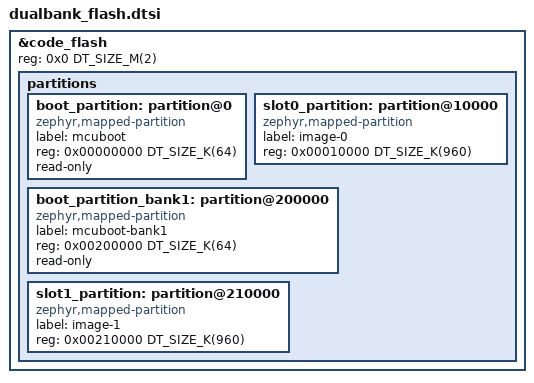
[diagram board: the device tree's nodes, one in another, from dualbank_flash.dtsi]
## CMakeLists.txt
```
cmake_minimum_required(VERSION 3.20.0)
find_package(Zephyr REQUIRED HINTS $ENV{ZEPHYR_BASE})
project(ra6m5_dualbank_xip)

target_sources(app PRIVATE
    src/main.c
    src/comms.c
    src/menu.c
    src/xmodem.c
    src/downloader_thread_entry.c
    src/blinky_thread_entry.c
    src/interrupt_maker.c)

if(CONFIG_BOOTLOADER_MCUBOOT)
  set(signed_hex ${ZEPHYR_BINARY_DIR}/zephyr.signed.hex)
  set(signed_bin ${ZEPHYR_BINARY_DIR}/zephyr.signed.bin)

  add_custom_target(bank_images ALL
    COMMAND ${CMAKE_COMMAND} -E copy ${signed_hex} ${ZEPHYR_BINARY_DIR}/app_bank0.hex
    COMMAND ${CMAKE_OBJCOPY} -I ihex -O ihex --change-addresses 0x200000
            ${signed_hex} ${ZEPHYR_BINARY_DIR}/app_bank1_rfp.hex
    COMMAND ${CMAKE_OBJCOPY} -I ihex -O ihex --change-addresses 0x100000
            ${signed_hex} ${ZEPHYR_BINARY_DIR}/app_bank1_jlink.hex
    COMMAND ${CMAKE_COMMAND} -E copy ${signed_bin} ${ZEPHYR_BINARY_DIR}/app_xmodem.bin
  )
  add_dependencies(bank_images ${logical_target_for_zephyr_elf})
endif()
```

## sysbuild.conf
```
SB_CONFIG_BOOTLOADER_MCUBOOT=y # Includes mcuboot

SB_CONFIG_MCUBOOT_MODE_DIRECT_XIP=y # Sets mcuboot to use direct xip

SB_CONFIG_MCUBOOT_DIRECT_XIP_GENERATE_VARIANT=n # stops sysbuild from making a slot 1 variant, wrong address

SB_CONFIG_BOOT_SIGNATURE_TYPE_ECDSA_P256=y # optional, more compact encryption
```

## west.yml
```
manifest:
  remotes:
    - name: P-Harwood
      url-base: https://github.com/P-Harwood

  projects:
    - name: zephyr
      remote: P-Harwood
      repo-path: zephyr_Exp
      revision: dualbank-v2.2.3
      clone-depth: 1
      import:
        name-allowlist:
          - cmsis_6
          - hal_renesas

    - name: mcuboot
      remote: P-Harwood
      repo-path: mcuboot
      revision: ra6m5-erase-size-v2
      path: bootloader/mcuboot

  self:
    path: applications/db_xip
```

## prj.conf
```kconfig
CONFIG_MCUBOOT_GENERATE_CONFIRMED_IMAGE=y # Make the confirmed file for initial flashing

CONFIG_FLASH=y # include the flash drivers
CONFIG_FLASH_MAP=y # include the named partitions so runtime code can access them
CONFIG_STREAM_FLASH=y # buffered flash writes, used by the image manager
CONFIG_IMG_MANAGER=y # Zephyrs tool for writing firmware into a slot

CONFIG_FLASH_RENESAS_RA_HP_BANK_SWAP=y # Includes flash_ex_op and bank swap
CONFIG_FLASH_EX_OP_ENABLED=y # enabled version of flash_ex_op

CONFIG_GPIO=y # gpio pins support
CONFIG_REBOOT=y # allows software rebooting

CONFIG_SERIAL=y
CONFIG_UART_INTERRUPT_DRIVEN=y # comms.c receives on the UART interrupt
CONFIG_CONSOLE=y # printk goes to the same UART, output only
CONFIG_PRINTK=y

# main thread stack size
CONFIG_MAIN_STACK_SIZE=2048
CONFIG_HW_STACK_PROTECTION=y
CONFIG_IMG_ERASE_PROGRESSIVELY=y


CONFIG_COUNTER=y
CONFIG_FLASH_RENESAS_RA_HP_IRQ_ENABLED=y
```

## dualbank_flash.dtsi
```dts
&code_flash {
	reg = <0x0 DT_SIZE_M(2)>;
	ranges = <0x0 0x0 DT_SIZE_M(3)>;

	partitions {
		#address-cells = <1>;
		#size-cells = <1>;
		ranges;

		boot_partition: partition@0 {
			compatible = "zephyr,mapped-partition";
			label = "mcuboot";
			reg = <0x00000000 DT_SIZE_K(64)>;
			read-only;
		};

		slot0_partition: partition@10000 {
			compatible = "zephyr,mapped-partition";
			label = "image-0";
			reg = <0x00010000 DT_SIZE_K(960)>;
		};
		boot_partition_bank1: partition@200000 {
			compatible = "zephyr,mapped-partition";
			label = "mcuboot-bank1";
			reg = <0x00200000 DT_SIZE_K(64)>;
			read-only;
		};

		slot1_partition: partition@210000 {
			compatible = "zephyr,mapped-partition";
			label = "image-1";
			reg = <0x00210000 DT_SIZE_K(960)>;
		};
	};
};
```

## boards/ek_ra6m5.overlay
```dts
#include "../dualbank_flash.dtsi"

/ {
	chosen {
		zephyr,code-partition = &slot0_partition;
	};
};
&agt0 {
	interrupts = <86 1>, <87 1>;
	renesas,count-source = "AGT_CLOCK_PCLKB";
	interrupt-names = "agti", "agtcmai";
	status = "okay";

	counter0: counter {
		status = "okay";
	};
};
```

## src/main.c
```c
#include <zephyr/kernel.h>
#include <zephyr/dfu/mcuboot.h>
#include "header.h"
#include <zephyr/drivers/gpio.h>

int main(void)
{
	dual_bank_info();
	return 0;
}
```

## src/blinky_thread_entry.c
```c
#include <zephyr/kernel.h>
#include <zephyr/drivers/gpio.h>
static const struct gpio_dt_spec led = GPIO_DT_SPEC_GET(DT_ALIAS(led0), gpios);


void blinky_thread_entry(void *p1, void *p2, void *p3)
{
    ARG_UNUSED(p1);
    ARG_UNUSED(p2);
    ARG_UNUSED(p3);
    if (!gpio_is_ready_dt(&led)) {
        return;
    }
    gpio_pin_configure_dt(&led, GPIO_OUTPUT_ACTIVE);
    while (1) {
        gpio_pin_toggle_dt(&led);
        k_msleep(2000);
    }
}
K_THREAD_DEFINE(blinky_tid, 1024, blinky_thread_entry,
                NULL, NULL, NULL, 7, 0, 0);
```

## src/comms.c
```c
#include "comms.h"


#include <zephyr/kernel.h>
#include <zephyr/device.h>
#include <zephyr/drivers/uart.h>


#if defined(COMMS_USB)
#include <zephyr/usb/usb_device.h>
#define COMMS_DEV_NODE  DT_NODELABEL(cdc_acm_uart0)
#else
#define COMMS_DEV_NODE  DT_CHOSEN(zephyr_console)
#endif


#define RX_QUEUE_BYTES  512


static const struct device *const comms_dev = DEVICE_DT_GET(COMMS_DEV_NODE);


K_MSGQ_DEFINE(rx_q, 1, RX_QUEUE_BYTES, 1);

void comms_flush(void)
{
    k_msgq_purge(&rx_q);
}

static void comms_rx_isr(const struct device *dev, void *user_data)
{
    ARG_UNUSED(user_data);

    uart_irq_update(dev);

    if (uart_irq_rx_ready(dev)) {
        uint8_t byte;

        while (uart_fifo_read(dev, &byte, 1) == 1) {
            (void)k_msgq_put(&rx_q, &byte, K_NO_WAIT);
        }
    }
}




int comms_open(void)
{
    if (!device_is_ready(comms_dev)) {
        return -ENODEV;
    }


#if defined(COMMS_USB)
    int rc = usb_enable(NULL);
    if (rc != 0 && rc != -EALREADY) {
        return rc;
    }
    uint32_t dtr = 0U;
    while (!dtr) {
        uart_line_ctrl_get(comms_dev, UART_LINE_CTRL_DTR, &dtr);
        k_msleep(10);
    }
#endif
    uart_irq_callback_user_data_set(comms_dev, comms_rx_isr, NULL);
    uart_irq_rx_enable(comms_dev);


    return 0;
}


void comms_send(uint8_t *p_src, uint32_t len)
{
    for (uint32_t i = 0U; i < len; i++) {
        uart_poll_out(comms_dev, p_src[i]);
    }
}


int comms_read(uint8_t *p_dest, uint32_t *len, uint32_t timeout_milliseconds)
{
    const bool    forever  = (timeout_milliseconds == NO_TIMEOUT);
    const int64_t deadline = forever ? 0 : (k_uptime_get() + timeout_milliseconds);




    
for (uint32_t i = 0U; i < *len; i++) {
        k_timeout_t wait;


        if (forever) {
            wait = K_FOREVER;
        } else {
            int64_t remaining = deadline - k_uptime_get();
            if (remaining <= 0) {
                *len = i;
                return COMMS_TIMEOUT;
            }
            wait = K_MSEC(remaining);
        }
        if (k_msgq_get(&rx_q, &p_dest[i], wait) != 0) {
            *len = i;
            return COMMS_TIMEOUT;
        }
    }
    return COMMS_OK;
}
```

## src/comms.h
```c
#ifndef COMMS_H_
#define COMMS_H_


#include <stdint.h>
#include <errno.h>


#define COMMS_UART


#define NO_TIMEOUT      0xFFFFFFFFU


#define COMMS_OK        0
#define COMMS_TIMEOUT   (-EAGAIN)


int  comms_open(void);
void comms_send(uint8_t *p_src, uint32_t len);
int  comms_read(uint8_t *p_dest, uint32_t *len, uint32_t timeout_milliseconds);
void comms_flush(void);

#endif
```

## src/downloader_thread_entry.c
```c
#include <zephyr/kernel.h>
#include <zephyr/storage/flash_map.h>
#include <stdio.h>
#include <string.h>
#include <zephyr/dfu/mcuboot.h>

#include "comms.h"
#include "menu.h"
#include "header.h"
#include "interrupt_maker.h"

// MCUBoot magic number to be placed in the header of the image
#define IMAGE_MAGIC 0x96f3b83d  


void downloader_thread_entry(void *p1, void *p2, void *p3)
{
    ARG_UNUSED(p1);
    ARG_UNUSED(p2);
    ARG_UNUSED(p3);


    // Check to see if UART is ready and status is ok
    if (comms_open() != 0) {
        // If the UART is not ready then exit with panic
        k_panic();
    }


    // Infinite loop of running menu during the thread
    while (1) {
        menu();
    }
}


// Define and instantly launch the downloader thread with a piority of 5
K_THREAD_DEFINE(downloader_tid, 4096, downloader_thread_entry,
                   NULL, NULL, NULL, 5, 0, 0);






// Struct which contains image version to be put into the header of the image
struct image_version {
    uint8_t  iv_major;
    uint8_t  iv_minor;
    uint16_t iv_revision;
    uint32_t iv_build_num;
};


// Image header which brings all the information together
struct image_header {
    uint32_t ih_magic;
    uint32_t ih_load_addr;
    uint16_t ih_hdr_size;            
    uint16_t ih_protect_tlv_size;    
    uint32_t ih_img_size;            
    uint32_t ih_flags;              
    struct image_version ih_ver;
    uint32_t _pad1;
};



/** @brief Check if dualbank mode is enabled
 *	@retval boolean is dualbank enabled
*/
static bool dual_bank_mode(void)
{
	bool enabled = (sys_read32(DUALSEL_ADDR) & BANKMD_MASK) == 0U;
	return enabled;
}

/** @brief Check if the banks have been swapped by checking the bank swap register
 *	@retval boolean is dualbank enabled
*/
static bool banks_swapped(void)
{
	bool swapped = (sys_read32(BANKSEL_ADDR) & BANKSWP_MASK) == 0U;
	return swapped;
}



static void send_str(const char *str)
{
	comms_send((uint8_t *)str, strlen(str));
}

/** @brief Prints image details such as version and size for a given slot
 *
 *	@retval void
 */
static void print_slot(const char *title, uint8_t area_id, off_t offset)
{
	char tx_str[80];
	struct mcuboot_img_header header;
	int rc;

	send_str("****************************\r\n");
	snprintf(tx_str, sizeof(tx_str), "* %s *\r\n", title);
	send_str(tx_str);
	send_str("****************************\r\n");

	rc = boot_read_bank_header(area_id, &header, sizeof(header));
	if (rc != 0) {
		snprintf(tx_str, sizeof(tx_str), "Image version:        <no valid header> (%d)\r\n", rc);
		send_str(tx_str);
		snprintf(tx_str, sizeof(tx_str), "Image start address:  0x%08lx\r\n", (unsigned long)offset);
		send_str(tx_str);
		return;
	}

	struct mcuboot_img_sem_ver image_version = header.h.v1.sem_ver;

	snprintf(tx_str, sizeof(tx_str), "Image version:        %u.%u (Rev: %u, Build: %u)\r\n",
		 image_version.major, image_version.minor, image_version.revision,
		 image_version.build_num);
	send_str(tx_str);

	snprintf(tx_str, sizeof(tx_str), "Image start address:  0x%08lx\r\n", (unsigned long)offset);
	send_str(tx_str);

	snprintf(tx_str, sizeof(tx_str), "Header size:          0x%04x (%u bytes)\r\n",
		 CONFIG_ROM_START_OFFSET, CONFIG_ROM_START_OFFSET);
	send_str(tx_str);

	snprintf(tx_str, sizeof(tx_str), "Image size:           0x%08x (%u bytes)\r\n",
		 header.h.v1.image_size, header.h.v1.image_size);
	send_str(tx_str);
}


void dual_bank_info(void)
{
	char tx_str[50];

	
	sprintf((char *)tx_str, "\n=== RA6M5 dual bank direct-XIP demo ===\n");
	comms_send(tx_str, strlen((char *)tx_str));

	sprintf((char *)tx_str, "Running image:        v%s\n", CONFIG_MCUBOOT_IMGTOOL_SIGN_VERSION);
	comms_send(tx_str, strlen((char *)tx_str));

	sprintf((char *)tx_str, "Code flash mode:      %s bank\n", dual_bank_mode() ? "dual" : "linear");
	comms_send(tx_str, strlen((char *)tx_str));

	sprintf((char *)tx_str, "Bank at address 0:    %s\n", banks_swapped() ? "bank 1 (swapped)" : "bank 0");
	comms_send(tx_str, strlen((char *)tx_str));

	sprintf((char *)tx_str, "DUALSEL:              0x%08x\n", sys_read32(DUALSEL_ADDR));
	comms_send(tx_str, strlen((char *)tx_str));

	sprintf((char *)tx_str, "BANKSEL / _SEL:       0x%08x / 0x%08x\n", sys_read32(BANKSEL_ADDR), sys_read32(BANKSEL_SEL_ADDR));
	comms_send(tx_str, strlen((char *)tx_str));

	sprintf((char *)tx_str, "Vector table (VTOR):  0x%08x\n", SCB->VTOR);
	comms_send(tx_str, strlen((char *)tx_str));

	printk("Interrupts during flash writes: %d, largest delay was %d us late\n",
	interrupts_during_write, most_late);

	print_slot("Primary Image Slot", PARTITION_ID(slot0_partition), PARTITION_OFFSET(slot0_partition));
	
	print_slot("Secondary Image Slot", PARTITION_ID(slot1_partition), PARTITION_OFFSET(slot1_partition));

	
	sprintf((char *)tx_str, "=======================================\n\n");
	comms_send(tx_str, strlen((char *)tx_str));
}
```

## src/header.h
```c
#ifndef HEADER_H_
#define HEADER_H_


void dual_bank_info(void);


#define DUALSEL_ADDR     DT_REG_ADDR(DT_NODELABEL(option_setting_dualsel))
#define BANKSEL_ADDR     0x0100A190U
#define BANKSEL_SEL_ADDR DT_REG_ADDR(DT_NODELABEL(option_setting_banksel_sel))

#define BANKMD_MASK  0x7U	/* Bank mode mask for DualSel register (0xF - 0b111) */
#define BANKSWP_MASK 0x7U	/* Bank Swap mask for BankSel register (0xF - 0b111) */

/* Bank 1 offset from the start of code flash, 0x200000 on every dual bank part */
#define FLASH_HP_BANK1_OFFSET                                                                      \
	(BSP_FEATURE_FLASH_HP_CF_DUAL_BANK_START - BSP_FEATURE_FLASH_CODE_FLASH_START)
    
#define enabled_led_index 2 /* The index of enabled - modify this value not max_led_index */
#define max_led_index 3 /* Maximum allowed enabled leds*/

#endif
```

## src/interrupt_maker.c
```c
#include "interrupt_maker.h"

volatile bool started_flash_write = false;
volatile bool ended_flash_write = false;
volatile int interrupts_during_write = 0;
volatile uint32_t interrupt_latency_us = 0;
volatile uint32_t most_late = 0;

static const struct device *const flash_write_counter = DEVICE_DT_GET(DT_NODELABEL(counter0));
static uint32_t alarm_due_ticks;

volatile bool flash_write_alarm_running = false;


static void arm_flash_write_alarm(const struct device *dev)
{
	struct counter_alarm_cfg alarm = {
		.callback = flash_write_alarm_callback,
		.ticks = counter_us_to_ticks(dev, FLASH_WRITE_ALARM_US),
	};
	uint32_t now;

	counter_get_value(dev, &now);
	alarm_due_ticks = (now - alarm.ticks) & AGT_COUNT_MASK;
	counter_set_channel_alarm(dev, 0, &alarm);
}


void flash_write_alarm_callback(const struct device *dev, uint8_t chan_id, uint32_t ticks,
				void *user_data)
{
	ARG_UNUSED(chan_id);
	ARG_UNUSED(user_data);

	if (started_flash_write && !ended_flash_write) {
		uint32_t ticks_late = (alarm_due_ticks - ticks) & AGT_COUNT_MASK;
		uint32_t us_late = counter_ticks_to_us(dev, ticks_late);

		interrupts_during_write++;
		if (us_late > most_late) {
			most_late = us_late;
		}
	}

	if (flash_write_alarm_running) {
		arm_flash_write_alarm(dev);
	}
}

void start_flash_write_alarm(void)
{
	counter_start(flash_write_counter);
	flash_write_alarm_running = true;
	arm_flash_write_alarm(flash_write_counter);
}

void stop_flash_write_alarm(void)
{
	flash_write_alarm_running = false;
	counter_cancel_channel_alarm(flash_write_counter, 0);
}
```

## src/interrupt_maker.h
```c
#ifndef FLAGS_H_
#define FLAGS_H_

#include <stdbool.h>
#include <stdint.h>
#include <zephyr/device.h>
#include <soc.h>
#include <zephyr/drivers/counter.h>

#define ALARM_CHANNEL_ID 0
#define ALARM_FLAGS 0


#define FLASH_WRITE_ALARM_US 100
#define AGT_COUNT_MASK       0xFFFFU


extern volatile bool started_flash_write;
extern volatile bool ended_flash_write;
extern volatile int interrupts_during_write;
extern volatile uint32_t interrupt_latency_us;
extern volatile uint32_t most_late;


void start_flash_write_alarm(void);
void stop_flash_write_alarm(void);
void flash_write_alarm_callback(const struct device *dev, uint8_t chan_id, uint32_t ticks,
				void *user_data);


#endif
```

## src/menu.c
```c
#include <zephyr/kernel.h>
#include <zephyr/sys/reboot.h>
#include <zephyr/dfu/mcuboot.h>
#include <zephyr/storage/flash_map.h>
#include <stdio.h>
#include <string.h>


#include "menu.h"
#include "header.h"
#include "comms.h"
#include "xmodem.h"


// UI Banner
const char *gp_banner[] = {
    "  /\\/\\   ___ _ __  _   _",
    " /    \\ / _ \\ '_ \\| | | |",
    "/ /\\/\\ \\  __/ | | | |_| |",
    "\\/    \\/\\___|_| |_|\\__,_|",
};
void menu(void)
{
    printk("New software version v1.4\n"); // Optional print statment, good for seeing software version
    printk("Inside Menu\n");


    uint8_t tx_str[80]; // buffer for text to be output
    uint8_t rx_str[20]; // buffer to hold receiving text
    int     err;


    // Start at a new line
    sprintf((char *)tx_str, "\n\r");
    comms_send(tx_str, strlen((char *)tx_str));


    //Print the banner
    for (uint8_t b = 0; b < 4; b++) {
        comms_send((uint8_t *)gp_banner[b], strlen(gp_banner[b]));
        comms_send((uint8_t *)"\n\r", 2);
    }
    // Print user options
    sprintf((char *)tx_str, "\n\r1 - Display image slot info\n\r");
    comms_send(tx_str, strlen((char *)tx_str));


    sprintf((char *)tx_str, "2 - Download new update image (XModem)\n\r");
    comms_send(tx_str, strlen((char *)tx_str));


    sprintf((char *)tx_str, "3 - Reboot\n\r");
    comms_send(tx_str, strlen((char *)tx_str));


    comms_send((uint8_t *)">", 1);


    // Prepare a variable to hold the user input
    rx_str[0] = 0;
    uint32_t len = 1;
    // Call comms_read to wait for user input and store the new input in rx_Str
    err = comms_read(rx_str, &len, NO_TIMEOUT);
    if (err != COMMS_OK) {
        return;    
    }
    // Echo the user input back
    comms_send(rx_str, 1);
    comms_send((uint8_t *)"\n\r", 2);


    // Switch the user input
    switch (rx_str[0])
    {
        case '1':
        {
            uint8_t tx_str[80]; // buffer for text to be output

            sprintf((char *)tx_str, "Opening dual bank info\n\r");
            comms_send(tx_str, strlen((char *)tx_str));
            // Display slot info  
            dual_bank_info();
            break;
        }
        case '2':
        {
            sprintf((char *)tx_str, "Start Xmodem transfer...\r\n");
            comms_send(tx_str, strlen((char *)tx_str));


            // Call Xmodem code which handles downloading and inserting new image
            unsigned char xm_err = XmodemDownloadAndProgramFlash();


            // Handle outcomes from Xmodem
            if (XM_OK == xm_err)
            {
                // Nothing to mark: on reset MCUboot boots the newest valid image
                // and swaps banks first if that image is in the secondary slot
                sprintf((char *)tx_str, "Image download successful - reboot (3) to apply\r\n");
                comms_send(tx_str, strlen((char *)tx_str));
            }
            else
            {
                switch (xm_err) {
                    case XM_ADDRESS_ERROR:
                        sprintf((char *)tx_str, "ERROR: Flash address invalid\r\n");
                        break;
                    case XM_COMMS_ERROR:
                        sprintf((char *)tx_str, "ERROR: Comms error during Xmodem download\r\n");
                        break;
                    case XM_TIMEOUT:
                        sprintf((char *)tx_str, "ERROR: Timeout during Xmodem download\r\n");
                        break;
                    case XM_PROG_FAIL:
                        sprintf((char *)tx_str, "ERROR: Flash programming error\r\n");
                        break;
                    default:
                        sprintf((char *)tx_str, "ERROR: unknown (%d)\r\n", xm_err);
                        break;
                }
                comms_send(tx_str, strlen((char *)tx_str));
            }
            break;
        }
        case '3':
        {
            // Reboot the device
            sprintf((char *)tx_str, "Resetting the device...\r\n");
            comms_send(tx_str, strlen((char *)tx_str));
            sys_reboot(SYS_REBOOT_COLD);
            break;
        }
        default:
        {
            break;
        }

    }
}
```

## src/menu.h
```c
#ifndef MENU_H_
#define MENU_H_
void menu(void);
#endif
```

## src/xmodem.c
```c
// xmodem.c
#include <string.h>
#include <zephyr/kernel.h>
#include <zephyr/dfu/flash_img.h>
#include <zephyr/dfu/mcuboot.h>
#include "xmodem.h"
#include "comms.h"
#include "interrupt_maker.h"
// Called by menu.c to download and program the new incoming image
unsigned char XmodemDownloadAndProgramFlash(void)
{
/*
XmodemDownloadAndProgramFlash() downloads data using the XModem protocol
developed in 1977 by Ward Christensen and programs it into the MCUboot
secondary slot (image-1).
The routine detects XM_ERRORs due to XM_TIMEOUTs, comms XM_ERRORs or invalid checksums.
The routine reports the following to the caller:
-Success
-Invalid address    (not implemented here as the address is checked prior to this
                    function being called)
-Comms XM_ERROR
-XM_TIMEOUT XM_ERROR
-Failure to program flash




Expects:
--------
Nothing - the destination is fixed by flash_img_init() to the MCUboot secondary
slot, so (unlike the original FSP version) there is no FlashAddress argument.


Returns:
--------
XM_OK               -   Download and Flash programming performed ok
XM_ADDRESS_ERROR    -   Address was either not on a 128-byte boundary or not in valid Flash
XM_COMMS_ERROR      -   Comms parity, framing or overrun XM_ERROR
XM_TIMEOUT          -   Transmitter did not respond to this receiver
XM_PROG_FAIL        -   Failed to program one or more bytes of the Flash memory
*/
    unsigned char   xm_ret;
    unsigned char   ExpectedBlkNum;
    unsigned char   RetryCounter;
    unsigned char   RxByteBufferIndex;
    unsigned char   checksum;
    unsigned char   StartCondition;
    unsigned char   RxByteBuffer[132] __aligned(4);
    uint8_t         tx_byte __aligned(4);
    uint32_t        rx_len;
    int             err;
    static struct flash_img_context flash_ctx;
    /* Target the MCUboot secondary slot (image-1). */
    // flash_img_init initalises context for writing to the flash
    if (flash_img_init(&flash_ctx) != 0)
    {
        return XM_PROG_FAIL;
    }
    // Drop anything typed after the menu choice, otherwise every frame is a byte out of step
    comms_flush();
    // first xmodem block number is 1
    ExpectedBlkNum = 1;
    StartCondition = 0;
    while(1)
    {
        //  {1}
        //  initialise Rx attempts
        RetryCounter = 10;


        //  decrement Rx attempts counter & get Rx byte with a 10 sec TIMEOUT repeat until Rx attempts is 0
        xm_ret = XM_TOUT;
        while ( (RetryCounter > 0) && (xm_ret == XM_TOUT) )
        {
            if (StartCondition == 0)
            {
                //  if this is the start of the xmodem frame
                //  send a NAK to the transmitter
                tx_byte = NAK;
                comms_send(&tx_byte, 1);    // Kick off the XModem transfer


                /* Request 132 bytes from host with a delay of 10 seconds */
                rx_len = 132;
                memset((void *)&RxByteBuffer[0], 0, 132);
                err = comms_read((uint8_t *)&RxByteBuffer[0], &rx_len, 10000);
                if(COMMS_OK == err)
                {
                    xm_ret = OK;
                }
                else if(COMMS_TIMEOUT == err)
                {
                    xm_ret = XM_TOUT;
                }
                else
                {
                    xm_ret = XM_ERROR;
                }
            }
            else
            {
                /* Request 132 bytes from host with a delay of 1 second */
                rx_len = 1;
                memset((void *)&RxByteBuffer[0], 0, 132);
                /* Get the first byte to check if it is EOT */
                err = comms_read((uint8_t *)&RxByteBuffer[0], &rx_len, 1000);
                if(COMMS_OK == err)
                {
                    xm_ret = OK;
                    if (EOT != RxByteBuffer[0])
                    {
                        /* Receive the rest of the frame */
                        rx_len = 132 - 1;
                        err = comms_read((uint8_t *)&RxByteBuffer[1], &rx_len, 1000);
                        if(COMMS_OK == err)
                        {
                            xm_ret = OK;
                        }
                        else if(COMMS_TIMEOUT == err)
                        {
                            xm_ret = XM_TOUT;
                        }
                        else
                        {
                            xm_ret = XM_ERROR;
                        }
                    }
                }
                else if(COMMS_TIMEOUT == err)
                {
                    xm_ret = XM_TOUT;
                }
                else
                {
                    xm_ret = XM_ERROR;
                }
            }
            RetryCounter--;
        }


        StartCondition = 1;


        if ( xm_ret == XM_ERROR )
        {
            return ( XM_COMMS_ERROR );
        }
        else if ( xm_ret == XM_TOUT )
        {
            //  if timed out after 10 attempts
            printk("timeout, %u bytes in last read\n", rx_len);
            return ( XM_TIMEOUT );
        }
        else
        {
            // if first received byte is 'end of frame'
            // return ACK to sender
            if ( RxByteBuffer[0] == EOT )
            {
                /* Flush the final buffered write before acknowledging. */
                err = flash_img_buffered_write(&flash_ctx, NULL, 0, true);
                if (err != 0)
                {
                    tx_byte = NAK;
                    comms_send(&tx_byte, 1);
                    tx_byte = CAN;
                    comms_send(&tx_byte, 1);
                    return ( XM_PROG_FAIL );
                }
                tx_byte = ACK;
                comms_send(&tx_byte, 1);
                return( XM_OK );
            }
            else
            {
                // data Rx ok
                // calculate the checksum of the data bytes only
                int cs = 0;
                for (RxByteBufferIndex=0; RxByteBufferIndex<128; RxByteBufferIndex++)
                {
                    cs += RxByteBuffer[RxByteBufferIndex + 3];
                }


                /* This int to unsigned char conversion needed to eliminate conversion warning with checksum calculation. */
                checksum = (unsigned char)cs;


                //  if SOH, BLK#, 255-BLK# or checksum not valid
                //  (BLK# is valid if the same as expected blk counter or is 1 less
                if ( !( (RxByteBuffer[0] == SOH) && ((RxByteBuffer[1] == ExpectedBlkNum) || (RxByteBuffer[1] == ExpectedBlkNum - 1) ) && (RxByteBuffer[2] + RxByteBuffer[1] == 255 ) && (RxByteBuffer[131] == checksum) ) )
                {
                    //  send NAK and loop back to (1)
                    printk("bad frame: %02x %02x %02x, sum %02x expected %02x\n",
                           RxByteBuffer[0], RxByteBuffer[1], RxByteBuffer[2],
                           RxByteBuffer[131], checksum);
                    tx_byte = NAK;
                    comms_send(&tx_byte, 1);
                }
                else
                {
                    //  if blk# is expected blk num
                    if ( RxByteBuffer[1] == ExpectedBlkNum )
                    {
                        //  Program the received data into flash
                        /* flash_img streams to the secondary slot and tracks the write
                           offset, so there is no manual address and no interrupt juggling
                           (the flash driver owns read-while-write). */

                        ended_flash_write = false;
                        started_flash_write = true;
                        start_flash_write_alarm();

                        err = flash_img_buffered_write(&flash_ctx, &RxByteBuffer[3], 128, false);

                        ended_flash_write = true;
                        stop_flash_write_alarm();




                        if(0 == err)
                        {
                            //  if prog routine passed ok increment block number
                            //  (flash_img advances the flash offset internally)
                            ExpectedBlkNum++;
                            tx_byte = ACK;
                            comms_send(&tx_byte, 1);


                            //  loop back to (1)
                        }
                        else
                        {
                            // prog fail
                            tx_byte = NAK;
                            comms_send(&tx_byte, 1);
                            // cancel xmodem download
                            tx_byte = CAN;
                            comms_send(&tx_byte, 1);


                            return( XM_PROG_FAIL );
                        }
                    }
                    else
                    {
                        //  block number is valid but this data block has already been received
                        //  send ACK and loop to (1)
                        tx_byte = ACK;
                        comms_send(&tx_byte, 1);
                    }
                }
            }
        }
    }
}
```

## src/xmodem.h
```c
// xmodem.h


#ifndef _XMODEM_H
#define _XMODEM_H


#define SOH                 0x01
#define EOT                 0x04
#define ACK                 0x06
#define NAK                 0x15
#define CAN                 0x18


#define XM_OK               0x00
#define XM_ADDRESS_ERROR    0x01
#define XM_COMMS_ERROR      0x02
#define XM_TIMEOUT          0x04
#define XM_PROG_FAIL        0x08


// status info
#define OK                  0
#define XM_ERROR            1
#define XM_TOUT             2




unsigned char XmodemDownloadAndProgramFlash(void);


#endif
```
